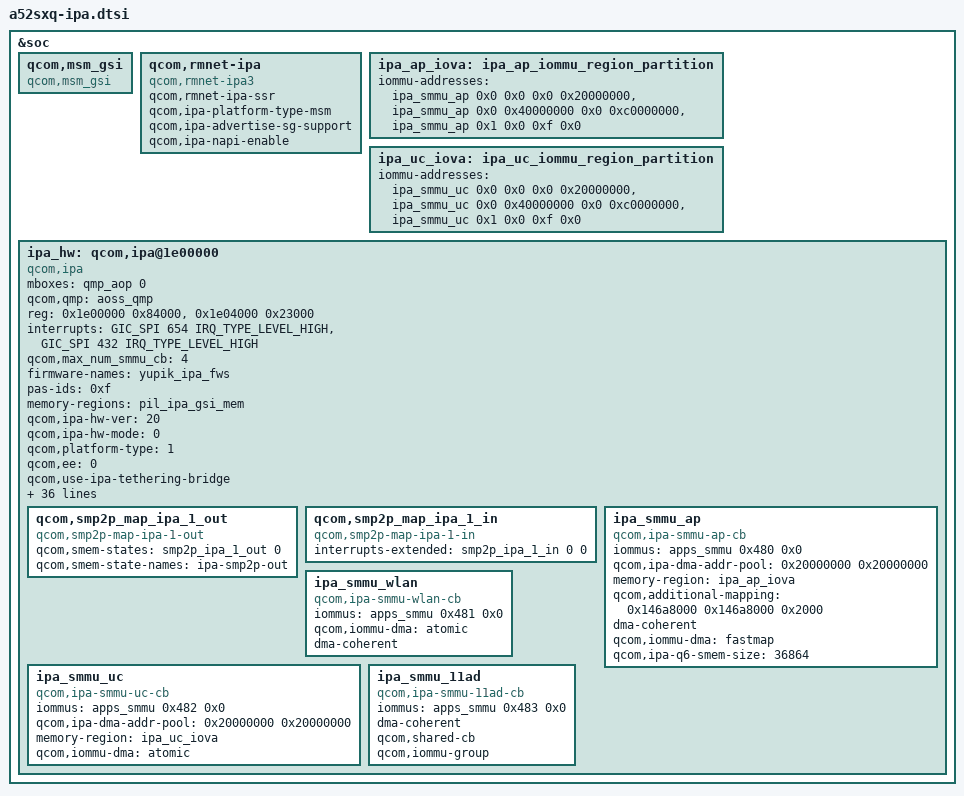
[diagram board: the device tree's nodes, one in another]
// SPDX-License-Identifier: BSD-3-Clause
/*
 * a52sxq: IPA v4.11 + GSI + rmnet_ipa for the Qualcomm 6.12 base (yupik.dtsi of
 * kernel.lnx.6.12.r70 has NO IPA nodes). Every value below is the phone's own 5.4 node
 * (downstream-dt/a52sxq-r02.dts, /soc/qcom,ipa@1e00000 and neighbours); only the lines marked
 * "6.12:" are new. Include from the conn fragment (needs labels rpmhcc, aggre2_noc, gem_noc,
 * mc_virt, cnoc2, apps_smmu, aoss_qmp, qmp_aop, smp2p_ipa_1_out/in, pil_ipa_gsi_mem: all
 * exist in bsp612/devicetree/qcom/yupik.dtsi).
 * NOT compiled into a dtb yet; NOT run on hardware.
 */
#include <dt-bindings/clock/qcom,rpmh.h>
#include <dt-bindings/interconnect/qcom,yupik.h>
#include <dt-bindings/interrupt-controller/arm-gic.h>

&soc {
	qcom,msm_gsi {
		compatible = "qcom,msm_gsi";
	};

	qcom,rmnet-ipa {
		compatible = "qcom,rmnet-ipa3";
		qcom,rmnet-ipa-ssr;
		qcom,ipa-platform-type-msm;
		qcom,ipa-advertise-sg-support;
		qcom,ipa-napi-enable;
	};

	/*
	 * 5.4 had a PIL node "qcom,ipa_fws" (qcom,pil-tz-generic, pas-id 0xf, /dev/subsys_yupik_ipa_fws).
	 * 6.12: PIL is gone; ipam loads the GSI firmware itself (ipa3_pil_load_ipa_fws ->
	 * qcom_mdt_load + qcom_scm_pas_auth_and_reset) from firmware-names/pas-ids/memory-regions
	 * on the IPA node. No userspace on the A52s opens /dev/subsys_yupik_ipa_fws (blob
	 * inventory), so no compat node is needed for it.
	 */

	/*
	 * 6.12: qcom,iommu-dma-addr-pool is no longer honoured by the IOMMU layer. The window is
	 * given by reserving everything OUTSIDE it with iommu-addresses (same 512 MiB window at
	 * 0x20000000 as the 5.4 pool), and the driver itself reads qcom,ipa-dma-addr-pool
	 * (ipa.c, AP/UC cb probe; it still falls back to the old name).
	 */
	ipa_ap_iova: ipa_ap_iommu_region_partition {
		iommu-addresses = <&ipa_smmu_ap 0x0 0x0 0x0 0x20000000>,
				  <&ipa_smmu_ap 0x0 0x40000000 0x0 0xc0000000>,
				  <&ipa_smmu_ap 0x1 0x0 0xf 0x0>;
	};

	ipa_uc_iova: ipa_uc_iommu_region_partition {
		iommu-addresses = <&ipa_smmu_uc 0x0 0x0 0x0 0x20000000>,
				  <&ipa_smmu_uc 0x0 0x40000000 0x0 0xc0000000>,
				  <&ipa_smmu_uc 0x1 0x0 0xf 0x0>;
	};

	ipa_hw: qcom,ipa@1e00000 {
		compatible = "qcom,ipa";
		mboxes = <&qmp_aop 0>;
		qcom,qmp = <&aoss_qmp>;		/* 6.12: ipa3_get_qmp() uses qmp_get(dev); unverified */
		reg = <0x1e00000 0x84000>, <0x1e04000 0x23000>;
		reg-names = "ipa-base", "gsi-base";
		interrupts = <GIC_SPI 654 IRQ_TYPE_LEVEL_HIGH>,
			     <GIC_SPI 432 IRQ_TYPE_LEVEL_HIGH>;
		interrupt-names = "ipa-irq", "gsi-irq";

		/*
		 * 6.12: the driver defaults to IPA_SMMU_CB_MAX (8) context banks and runs its
		 * post-init only after that many cb sub-devices probed. Must equal the number of
		 * ipa_smmu_* children below (AP, WLAN, UC, 11AD = 4).
		 */
		qcom,max_num_smmu_cb = <4>;
		/* 6.12: firmware load without PIL (see above) */
		firmware-names = "yupik_ipa_fws";
		pas-ids = <0xf>;
		memory-regions = <&pil_ipa_gsi_mem>;	/* 0x8b710000 + 0xa000, as on 5.4 */

		qcom,ipa-hw-ver = <20>;		/* IPA v4.11 */
		qcom,ipa-hw-mode = <0>;
		qcom,platform-type = <1>;
		qcom,ee = <0>;
		qcom,use-ipa-tethering-bridge;
		qcom,modem-cfg-emb-pipe-flt;
		qcom,ipa-wdi3-over-gsi;
		qcom,arm-smmu;
		qcom,smmu-fast-map;
		qcom,use-64-bit-dma-mask;
		qcom,ipa-endp-delay-wa-v2;
		qcom,eth-bridging-not-supported;
		qcom,bw-monitor-supported;
		qcom,lan-rx-napi;
		qcom,tx-napi;
		qcom,wan-use-skb-page;
		qcom,rmnet-ctl-enable;
		qcom,use-gsi-ipa-fw = "yupik_ipa_fws";
		qcom,tx-wrapper-cache-max-size = <400>;
		qcom,ipa-gpi-event-rp-ddr;
		clock-names = "core_clk";
		clocks = <&rpmhcc RPMH_IPA_CLK>;
		qcom,interconnect,num-cases = <5>;
		qcom,interconnect,num-paths = <3>;
		interconnects = <&aggre2_noc MASTER_IPA &gem_noc SLAVE_LLCC>,
				<&mc_virt MASTER_LLCC &mc_virt SLAVE_EBI1>,
				<&gem_noc MASTER_APPSS_PROC &cnoc2 SLAVE_IPA_CFG>;
		interconnect-names = "ipa_to_llcc", "llcc_to_ebi1", "appss_to_ipa";
		qcom,no-vote = <0 0 0 0 0 0>;
		qcom,svs2 = <150000 600000 150000 1804000 0 74000>;
		qcom,svs = <625000 1200000 625000 3072000 0 150000>;
		qcom,nominal = <1250000 2400000 1250000 6220800 0 400000>;
		qcom,turbo = <2000000 3500000 2000000 7219200 0 400000>;
		qcom,bus-vector-names = "MIN", "SVS2", "SVS", "NOMINAL", "TURBO";
		qcom,throughput-threshold = <600 2500 5000>;
		qcom,scaling-exceptions = <>;

		qcom,smp2p_map_ipa_1_out {
			compatible = "qcom,smp2p-map-ipa-1-out";
			qcom,smem-states = <&smp2p_ipa_1_out 0>;
			qcom,smem-state-names = "ipa-smp2p-out";
		};

		qcom,smp2p_map_ipa_1_in {
			compatible = "qcom,smp2p-map-ipa-1-in";
			interrupts-extended = <&smp2p_ipa_1_in 0 0>;
			interrupt-names = "ipa-smp2p-in";
		};

		ipa_smmu_ap: ipa_smmu_ap {
			compatible = "qcom,ipa-smmu-ap-cb";
			iommus = <&apps_smmu 0x480 0x0>;
			qcom,ipa-dma-addr-pool = <0x20000000 0x20000000>;
			memory-region = <&ipa_ap_iova>;		/* 6.12 */
			qcom,additional-mapping = <0x146a8000 0x146a8000 0x2000>; /* modem tables in IMEM */
			dma-coherent;
			qcom,iommu-dma = "fastmap";
			qcom,ipa-q6-smem-size = <36864>;
		};

		ipa_smmu_wlan: ipa_smmu_wlan {
			compatible = "qcom,ipa-smmu-wlan-cb";
			iommus = <&apps_smmu 0x481 0x0>;
			qcom,iommu-dma = "atomic";
			dma-coherent;
		};

		ipa_smmu_uc: ipa_smmu_uc {
			compatible = "qcom,ipa-smmu-uc-cb";
			iommus = <&apps_smmu 0x482 0x0>;
			qcom,ipa-dma-addr-pool = <0x20000000 0x20000000>;
			memory-region = <&ipa_uc_iova>;		/* 6.12 */
			qcom,iommu-dma = "atomic";
		};

		/*
		 * On the phone's 5.4 tree. The A52s has no 11ad radio; if this cb fails to probe on
		 * 6.12 (qcom,shared-cb / qcom,iommu-group handling), delete it and set
		 * qcom,max_num_smmu_cb = <3> (what the other SM7325 port runs).
		 */
		ipa_smmu_11ad: ipa_smmu_11ad {
			compatible = "qcom,ipa-smmu-11ad-cb";
			iommus = <&apps_smmu 0x483 0x0>;
			dma-coherent;
			qcom,shared-cb;
			qcom,iommu-group;
		};
	};
};
